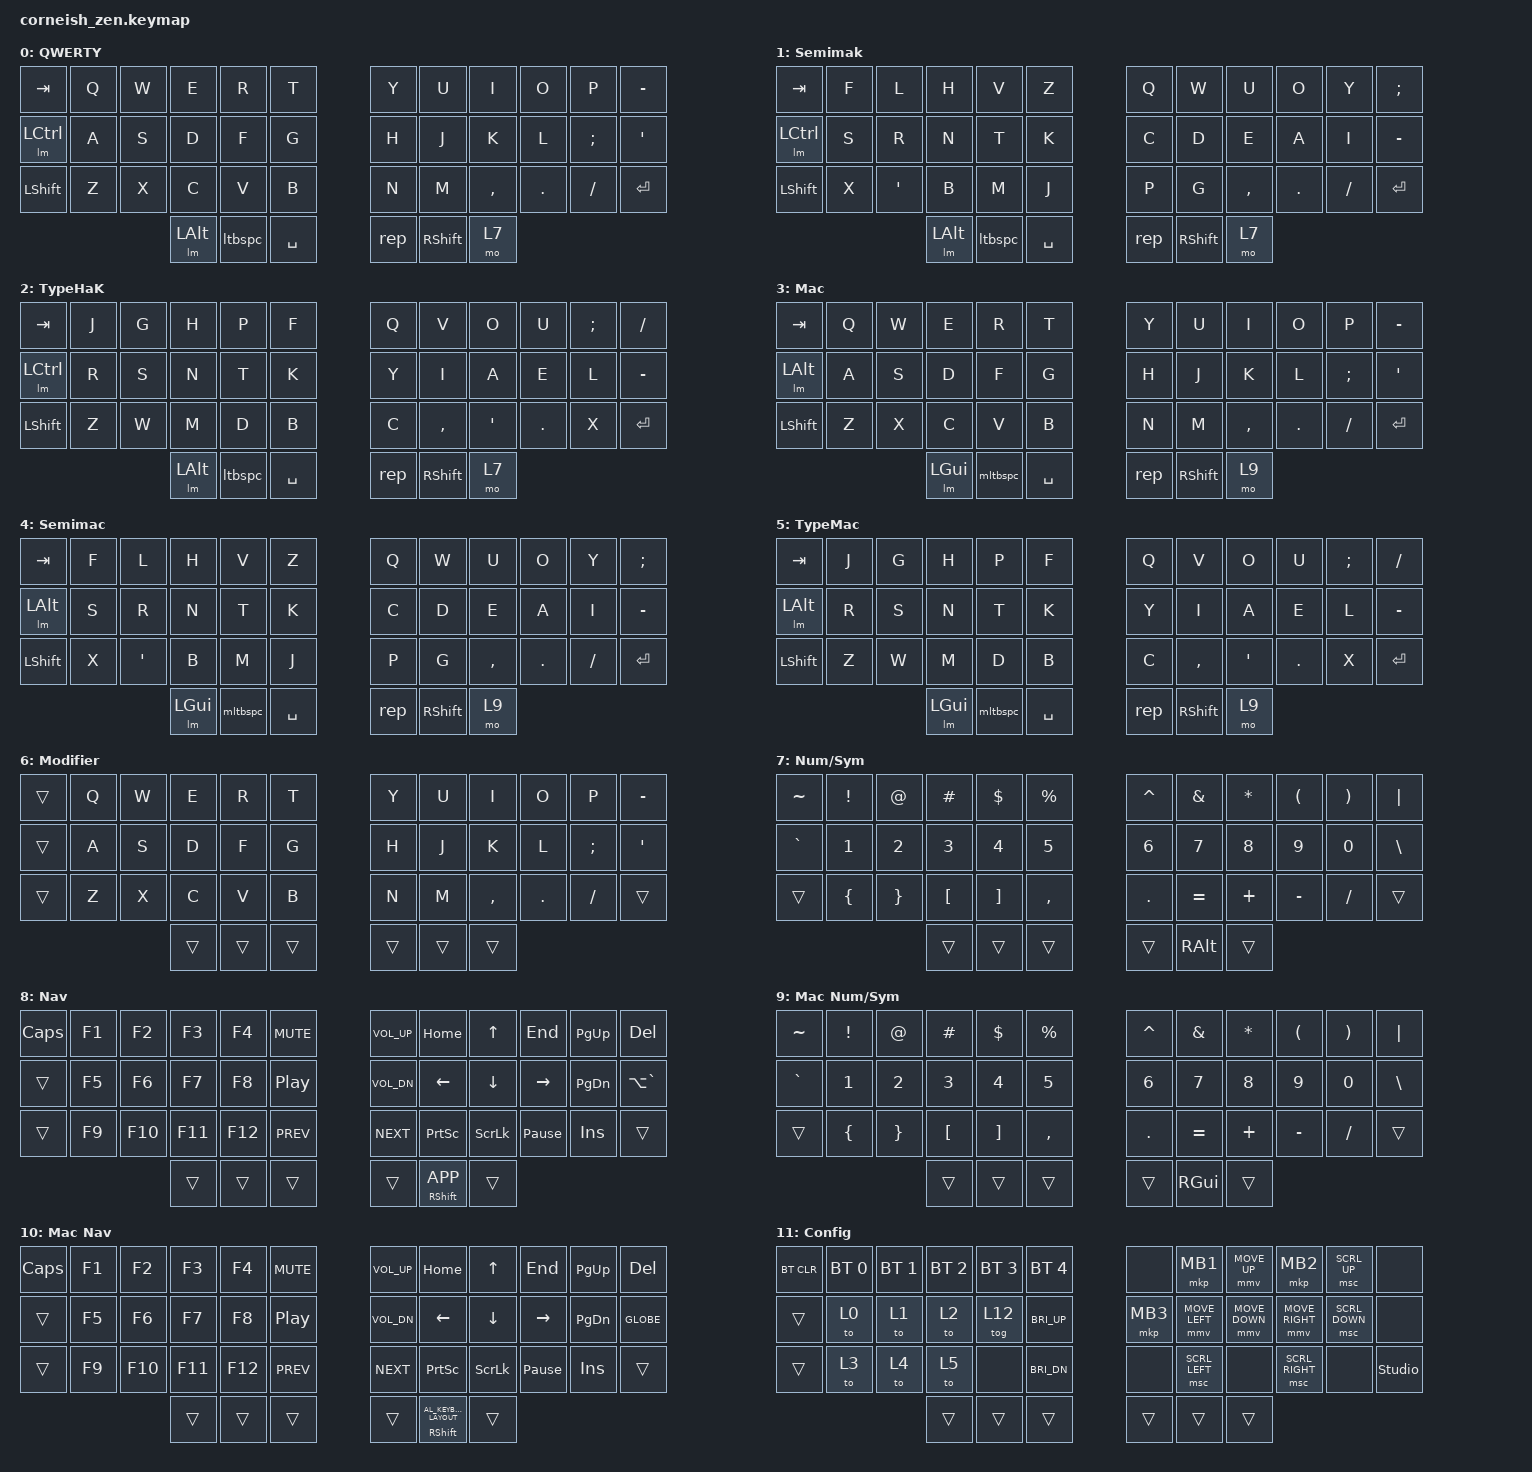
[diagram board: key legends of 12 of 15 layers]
/*
*
* Copyright (c) 2021 Darryl deHaan
* SPDX-License-Identifier: MIT
*
*/

#include <behaviors.dtsi>
#include <dt-bindings/zmk/keys.h>
#include <dt-bindings/zmk/bt.h>
#include <dt-bindings/zmk/outputs.h>

#define ZMK_POINTING_DEFAULT_MOVE_VAL 1800  // default: 600
#define ZMK_POINTING_DEFAULT_SCRL_VAL 20   // default: 10

#include <dt-bindings/zmk/pointing.h>

//Taipo Config
// CONFIG
#define COMBO_TIMEOUT 70
#define COMBO_LAYERS 12
#define STICKY_TIMEOUT 500
#define MOUSE_LEFT 13
#define MOUSE_RIGHT 14

// LEFT SIDE
#define TLI 4 // TOP
#define TLM 3 // TOP
#define TLR 2 // TOP
#define TLP 1 // TOP
#define BLI 16 // BOTTOM
#define BLM 15 // BOTTOM
#define BLR 14 // BOTTOM
#define BLP 13 // BOTTOM
#define LOT 38 // O-THUMB
#define LIT 37 // I-THUMB

// RIGHT SIDE
#define TRI 7 // TOP
#define TRM 8 // TOP
#define TRR 9 // TOP
#define TRP 10 // TOP
#define BRI 19 // BOTTOM
#define BRM 20 // BOTTOM
#define BRR 21 // BOTTOM
#define BRP 22 // BOTTOM
#define ROT 39 // O-THUMB
#define RIT 40 // I-THUMB

&sk {
    release-after-ms = <STICKY_TIMEOUT>;
    quick-release;
};

// 00 01 02 03 04 05	06 07 08 09 10 11
// 12 13 14 15 16 17	18 19 20 21 22 23
// 24 25 26 27 28 29	30 31 32 33 34 35
//          36 37 38	39 40 41


/ {
    chosen {
        zmk,physical-layout = &foostan_corne_6col_layout;
        // zmk,physical-layout = &foostan_corne_5col_layout;
    };
};

/ {
    behaviors {
        kton: key_toggle_on_only {
            compatible = "zmk,behavior-key-toggle";
            #binding-cells = <1>;
            display-name = "Key Toggle On";
            toggle-mode = "on";
        };
        ktoff: key_toggle_off_only {
            compatible = "zmk,behavior-key-toggle";
            #binding-cells = <1>;
            display-name = "Key Toggle Off";
            toggle-mode = "off";
        };
    };
};

/ {
    macros {
        lm: lm {
            compatible = "zmk,behavior-macro-one-param";
            #binding-cells = <1>;
            bindings
                = <&macro_press &mo 6>
                , <&macro_param_1to1>
                , <&macro_press &kp MACRO_PLACEHOLDER>
                , <&macro_pause_for_release>
                , <&macro_param_1to1>
                , <&macro_release &kp MACRO_PLACEHOLDER>
                , <&macro_release &mo 6>
                ;
        };
        skgl: skgl {
            compatible = "zmk,behavior-macro-one-param";
            #binding-cells = <1>;
            bindings
                = <&macro_press &sk GLOBE>
                , <&macro_param_1to1>
                , <&macro_press &sk MACRO_PLACEHOLDER>
                , <&macro_pause_for_release>
                , <&macro_param_1to1>
                , <&macro_release &sk MACRO_PLACEHOLDER>
                , <&macro_release &sk GLOBE>
                ;
        };
        sko: sko {
            compatible = "zmk,behavior-macro-one-param";
            #binding-cells = <1>;
            bindings
                = <&macro_param_1to1>
                , <&macro_press &sk MACRO_PLACEHOLDER>
                , <&macro_pause_for_release>
                , <&macro_param_1to1>
                , <&macro_release &sk MACRO_PLACEHOLDER>
                , <&macro_wait_time STICKY_TIMEOUT>
                , <&macro_param_1to1>
                , <&macro_release &kp MACRO_PLACEHOLDER>
                ;
        };
        modoff: modoff {
            compatible = "zmk,behavior-macro";
            #binding-cells = <0>;
            bindings
                = <&macro_release &kp LGUI &kp LALT &kp LCTRL &kp LSHFT>
                ;
        };
        modoffent: modoffent {
            compatible = "zmk,behavior-macro";
            #binding-cells = <0>;
            bindings
                = <&macro_press &kp ENTER>
                , <&macro_release &kp LGUI &kp LALT &kp LCTRL &kp LSHFT>
                , <&macro_pause_for_release>
                , <&macro_release &kp ENTER>
                ;
        };
    };
};

/ {
    conditional_layers {
        compatible = "zmk,conditional-layers";
        config {
            if-layers = <7 8>;
            then-layer = <11>;
        };
        macconfig {
            if-layers = <9 10>;
            then-layer = <11>;
        };
    };
};

#define rep key_repeat // Repeat Key Alias
#define ltbspc lt 8 BSPC //Backspace when tapped, nav layer when held
#define mltbspc lt 10 BSPC //Backspace when tapped, mac nav layer when held

/ {

    combos {
        compatible = "zmk,combos";
        #include "taipo.dtsi"

        combo_esc {
            timeout-ms = <50>;
            key-positions = <0 1>;
            bindings = <&kp ESC>;
        };
        combo_bspc {
            timeout-ms = <50>;
            key-positions = <11 23>;
            bindings = <&kp BSPC>;
        };
        combo_lgui {
            timeout-ms = <50>;
            key-positions = <36 37>;
            bindings = <&lm LGUI>;
			layers = <0 1 2 7 8>;
        };
        combo_rgui {
            timeout-ms = <50>;
            key-positions = <40 41>;
            bindings = <&lm RGUI>;
            layers = <0 1 2 7 8>;
        };
        combo_lctrl {
            timeout-ms = <50>;
            key-positions = <36 37>;
            bindings = <&lm LCTRL>;
			layers = <3 4 5 9 10>;
        };
        combo_rctrl {
            timeout-ms = <50>;
            key-positions = <40 41>;
            bindings = <&lm RCTRL>;
			layers = <3 4 5 9 10>;
        };
        combo_globe {
            timeout-ms = <50>;
            key-positions = <23 35>;
            bindings = <&lm GLOBE>;
			layers = <3 4 5 9 10>;
        };
        combo_taipo_off {
            timeout-ms = <50>;
            key-positions = <36 41>;
            bindings = <&tog 12>;
			layers = <12>;
        };
        combo_taipo_on_l {
            timeout-ms = <50>;
            key-positions = <00 12 24>;
            bindings = <&tog 12>;
			layers = <0 1 2 3 4 5 6 7 8 9 10 11>;
        };
        combo_taipo_on_r {
            timeout-ms = <50>;
            key-positions = <11 23 35>;
            bindings = <&tog 12>;
			layers = <0 1 2 3 4 5 6 7 8 9 10 11>;
        };
    };

    keymap {
        compatible = "zmk,keymap";

        default_layer {     //0
            display-name = "QWERTY";
// -------------------------------------------------------------------------------
// |  TAB |  Q  |  W  |  E  |  R  |  T  |   |  Y  |  U   |  I  |  O  |  P  |  -  |
// | CTRL |  A  |  S  |  D  |  F  |  G  |   |  H  |  J   |  K  |  L  |  ;  |  '  |
// | SHFT |  Z  |  X  |  C  |  V  |  B  |   |  N  |  M   |  ,  |  .  |  /  | ENT |
//                    | ALT |  BS | SPC |   | REP | SHFT | NUM |
            bindings = <
&kp TAB   &kp Q &kp W &kp E &kp R &kp T   &kp Y &kp U  &kp I     &kp O   &kp P    &kp MINUS
&lm LCTRL &kp A &kp S &kp D &kp F &kp G   &kp H &kp J  &kp K     &kp L   &kp SEMI &kp SQT
&kp LSHFT &kp Z &kp X &kp C &kp V &kp B   &kp N &kp M  &kp COMMA &kp DOT &kp FSLH &kp RET
             &lm LALT &ltbspc &kp SPACE   &rep &kp RSHFT &mo 7
            >;
        };

        semimak_layer {     //1
            display-name = "Semimak";
// -------------------------------------------------------------------------------
// |  TAB |  F  |  L  |  H  |  V  |  Z  |   |  Q  |  W   |  U  |  O  |  Y  |  ;  |
// | CTRL |  S  |  R  |  N  |  T  |  K  |   |  C  |  D   |  E  |  A  |  I  |  -  |
// | SHFT |  X  |  '  |  B  |  M  |  J  |   |  P  |  G   |  ,  |  .  |  /  | ENT |
//                    | ALT |  BS | SPC |   | REP | SHFT | NUM |
            bindings = <
&kp TAB   &kp F &kp L   &kp H &kp V &kp Z   &kp Q &kp W  &kp U     &kp O   &kp Y    &kp SEMI
&lm LCTRL &kp S &kp R   &kp N &kp T &kp K   &kp C &kp D  &kp E     &kp A   &kp I    &kp MINUS
&kp LSHFT &kp X &kp SQT &kp B &kp M &kp J   &kp P &kp G  &kp COMMA &kp DOT &kp FSLH &kp RET
               &lm LALT &ltbspc &kp SPACE   &rep &kp RSHFT &mo 7
            >;
        };

        typehack_layer {    //2
            display-name = "TypeHaK";
// -------------------------------------------------------------------------------
// |  TAB |  J  |  G  |  H  |  P  |  F  |   |  Q  |  V   |  O  |  U  |  ;  |  /  |
// | CTRL |  R  |  S  |  N  |  T  |  K  |   |  Y  |  I   |  A  |  E  |  L  |  -  |
// | SHFT |  Z  |  W  |  M  |  D  |  B  |   |  C  |  ,   |  '  |  .  |  X  | ENT |
//                    | ALT |  BS | SPC |   | REP | SHFT | NUM |
            bindings = <
&kp TAB   &kp J &kp G &kp H &kp P &kp F   &kp Q &kp V     &kp O   &kp U   &kp SEMI &kp FSLH
&lm LCTRL &kp R &kp S &kp N &kp T &kp K   &kp Y &kp I     &kp A   &kp E   &kp L    &kp MINUS
&kp LSHFT &kp Z &kp W &kp M &kp D &kp B   &kp C &kp COMMA &kp SQT &kp DOT &kp X    &kp RET
             &lm LALT &ltbspc &kp SPACE   &rep &kp RSHFT &mo 7
            >;
        };

        mac_layer {     //3
            display-name = "Mac";
// -------------------------------------------------------------------------------
// |  TAB |  Q  |  W  |  E  |  R  |  T  |   |  Y  |  U   |  I  |  O  |  P  |  -  |
// |  ALT |  A  |  S  |  D  |  F  |  G  |   |  H  |  J   |  K  |  L  |  ;  |  '  |
// | SHFT |  Z  |  X  |  C  |  V  |  B  |   |  N  |  M   |  ,  |  .  |  /  | ENT |
//                    | GUI |  BS | SPC |   | REP | SHFT | NUM |
            bindings = <
&kp TAB   &kp Q &kp W &kp E &kp R &kp T   &kp Y &kp U  &kp I     &kp O   &kp P    &kp MINUS
&lm LALT  &kp A &kp S &kp D &kp F &kp G   &kp H &kp J  &kp K     &kp L   &kp SEMI &kp SQT
&kp LSHFT &kp Z &kp X &kp C &kp V &kp B   &kp N &kp M  &kp COMMA &kp DOT &kp FSLH &kp RET
            &lm LGUI &mltbspc &kp SPACE   &rep &kp RSHFT &mo 9
            >;
        };

        semimac_layer {     //4
            display-name = "Semimac";
// -------------------------------------------------------------------------------
// |  TAB |  F  |  L  |  H  |  V  |  Z  |   |  Q  |  W   |  U  |  O  |  Y  |  ;  |
// |  ALT |  S  |  R  |  N  |  T  |  K  |   |  C  |  D   |  E  |  A  |  I  |  -  |
// | SHFT |  X  |  '  |  B  |  M  |  J  |   |  P  |  G   |  ,  |  .  |  /  | ENT |
//                    | GUI |  BS | SPC |   | REP | SHFT | NUM |
            bindings = <
&kp TAB   &kp F &kp L   &kp H &kp V &kp Z   &kp Q &kp W  &kp U     &kp O   &kp Y    &kp SEMI
&lm LALT  &kp S &kp R   &kp N &kp T &kp K   &kp C &kp D  &kp E     &kp A   &kp I    &kp MINUS
&kp LSHFT &kp X &kp SQT &kp B &kp M &kp J   &kp P &kp G  &kp COMMA &kp DOT &kp FSLH &kp RET
              &lm LGUI &mltbspc &kp SPACE   &rep &kp RSHFT &mo 9
            >;
        };

        typemack_layer {    //5
            display-name = "TypeMac";
// -------------------------------------------------------------------------------
// |  TAB |  J  |  G  |  H  |  P  |  F  |   |  Q  |  V   |  O  |  U  |  ;  |  /  |
// |  ALT |  R  |  S  |  N  |  T  |  K  |   |  Y  |  I   |  A  |  E  |  L  |  -  |
// | SHFT |  Z  |  W  |  M  |  D  |  B  |   |  C  |  ,   |  '  |  .  |  X  | ENT |
//                    | GUI |  BS | SPC |   | REP | SHFT | NUM |
            bindings = <
&kp TAB   &kp J &kp G &kp H &kp P &kp F   &kp Q &kp V     &kp O   &kp U   &kp SEMI &kp FSLH
&lm LALT  &kp R &kp S &kp N &kp T &kp K   &kp Y &kp I     &kp A   &kp E   &kp L    &kp MINUS
&kp LSHFT &kp Z &kp W &kp M &kp D &kp B   &kp C &kp COMMA &kp SQT &kp DOT &kp X    &kp RET
            &lm LGUI &mltbspc &kp SPACE   &rep &kp RSHFT &mo 9
            >;
        };

        modifier_layer {    //6
            display-name = "Modifier";
// ------------------------------------------------------------------------------
// |     |  Q  |  W  |  E  |  R  |  T  |   |  Y  |  U   |  I  |  O  |  P  |  /  |
// |     |  A  |  S  |  D  |  F  |  G  |   |  H  |  J   |  K  |  L  |  ;  |  '  |
// |     |  Z  |  X  |  C  |  V  |  B  |   |  N  |  M   |  ,  |  .  |  /  |     |
//                   |     |     |     |   |     |      |     |
            bindings = <
&trans &kp Q &kp W &kp E &kp R &kp T   &kp Y &kp U  &kp I     &kp O   &kp P    &kp MINUS
&trans &kp A &kp S &kp D &kp F &kp G   &kp H &kp J  &kp K     &kp L   &kp SEMI &kp SQT
&trans &kp Z &kp X &kp C &kp V &kp B   &kp N &kp M  &kp COMMA &kp DOT &kp FSLH &trans  
                &trans &trans &trans   &trans &trans &trans  
            >;
        };

        number_layer {      //7
            display-name = "Num/Sym";
// -----------------------------------------------------------------------------
// |  ~  |  !  |  @  |  #  |  $  |  %  |   |  ^  |  &  |  *  |  (  |  )  |  |  |
// |  `  |  1  |  2  |  3  |  4  |  5  |   |  6  |  7  |  8  |  9  |  0  |  \  |
// |     |  {  |  }  |  [  |  ]  |  ,  |   |  .  |  =  |  +  |  -  |  /  |     |
//                   |     |     |     |   |     | ALT |     |
            bindings = <
&kp TILDE &kp EXCL  &kp AT   &kp HASH &kp DLLR &kp PRCNT   &kp CARET &kp AMPS   &kp STAR &kp LPAR  &kp RPAR &kp PIPE
&kp GRAVE &kp N1    &kp N2   &kp N3   &kp N4   &kp N5      &kp N6    &kp N7     &kp N8   &kp N9    &kp N0   &kp BSLH
&trans    &kp LBRC  &kp RBRC &kp LBKT &kp RBKT &kp COMMA   &kp DOT   &kp EQUAL  &kp PLUS &kp MINUS &kp FSLH &trans
                          	        &trans &trans &trans   &trans &kp RALT &trans
            >;
        };

        navigation_layer {  //8
            display-name = "Nav";
// -----------------------------------------------------------------------------
// | CAP |  F1 |  F2 |  F3 |  F4 | MUT |   | VUP | HME |  UP | END | PGU | DEL |
// |     |  F5 |  F6 |  F7 |  F8 | PP  |   | VDN | LFT | DWN | RGT | PGD |     |
// |     |  F9 | F10 | F11 | F12 | PRV |   | NXT | PRN | SCL | PSE | INS |     |
//                   |     |     |     |   |     |     |     |
            bindings = <
&kp CAPS &kp F1 &kp F2  &kp F3  &kp F4  &kp C_MUTE   &kp C_VOL_UP &kp HOME  &kp UP   &kp END         &kp PG_UP &kp DEL
&trans   &kp F5 &kp F6  &kp F7  &kp F8  &kp C_PP     &kp C_VOL_DN &kp LEFT  &kp DOWN &kp RIGHT       &kp PG_DN &kp LA(GRAVE)
&trans   &kp F9 &kp F10 &kp F11 &kp F12 &kp C_PREV   &kp C_NEXT   &kp PSCRN &kp SLCK &kp PAUSE_BREAK &kp INS   &trans
                              &trans &trans &trans   &trans &mt RSHFT K_APP &trans
            >;
        };

        macnum_layer {      //9
            display-name = "Mac Num/Sym";
// -----------------------------------------------------------------------------
// |  ~  |  !  |  @  |  #  |  $  |  %  |   |  ^  |  &  |  *  |  (  |  )  |  |  |
// |  `  |  1  |  2  |  3  |  4  |  5  |   |  6  |  7  |  8  |  9  |  0  |  \  |
// |     |  {  |  }  |  [  |  ]  |  ,  |   |  .  |  =  |  +  |  -  |  /  |     |
//                   |     |     |     |   |     | GUI |     |
            bindings = <
&kp TILDE &kp EXCL  &kp AT   &kp HASH &kp DLLR &kp PRCNT   &kp CARET &kp AMPS   &kp STAR &kp LPAR  &kp RPAR &kp PIPE
&kp GRAVE &kp N1    &kp N2   &kp N3   &kp N4   &kp N5      &kp N6    &kp N7     &kp N8   &kp N9    &kp N0   &kp BSLH
&trans    &kp LBRC  &kp RBRC &kp LBKT &kp RBKT &kp COMMA   &kp DOT   &kp EQUAL  &kp PLUS &kp MINUS &kp FSLH &trans
                          	        &trans &trans &trans   &trans &kp RGUI &trans
            >;
        };

        macnav_layer {      //10
            display-name = "Mac Nav";
// -----------------------------------------------------------------------------
// | CAP |  F1 |  F2 |  F3 |  F4 | MUT |   | VUP | HME |  UP | END | PGU | DEL |
// |     |  F5 |  F6 |  F7 |  F8 | PP  |   | VDN | LFT | DWN | RGT | PGD |     |
// |     |  F9 | F10 | F11 | F12 | PRV |   | NXT | PRN | SCL | PSE | INS |     |
//                   |     |     |     |   |     |     |     |
            bindings = <
&kp CAPS &kp F1 &kp F2  &kp F3  &kp F4  &kp C_MUTE   &kp C_VOL_UP &kp HOME  &kp UP   &kp END         &kp PG_UP &kp DEL
&trans   &kp F5 &kp F6  &kp F7  &kp F8  &kp C_PP     &kp C_VOL_DN &kp LEFT  &kp DOWN &kp RIGHT       &kp PG_DN &kp GLOBE
&trans   &kp F9 &kp F10 &kp F11 &kp F12 &kp C_PREV   &kp C_NEXT   &kp PSCRN &kp SLCK &kp PAUSE_BREAK &kp INS   &trans
                              &trans &trans &trans   &trans &mt RSHFT C_AL_KEYBOARD_LAYOUT &trans
            >;
        };

        config_layer {      //11
            display-name = "Config";
// --------------------------------------------------------------------------------------
// | BTCLR | BT1 | BT2 | BT3 | BT4 | BT5 |   |     | MB1  | MSUP | MB2  | SCUP |        |
// |       | QWE | SEM | TYP | TAI |     |   | MB3 | MSLF | MSDN | MSRT | SCDN |        |
// |       | MAC | SMC | TYM |     |     |   |     | SCLF |      | SCRT |      | UNLOCK |
//                     |     |     |     |   |     |      |      |
            bindings = <
&bt BT_CLR &bt BT_SEL 0 &bt BT_SEL 1 &bt BT_SEL 2 &bt BT_SEL 3 &bt BT_SEL 4   &none    &mkp MB1       &mmv MOVE_UP   &mkp MB2        &msc SCRL_UP   &none
&trans     &to 0        &to 1        &to 2        &tog 12      &kp C_BRI_UP   &mkp MB3 &mmv MOVE_LEFT &mmv MOVE_DOWN &mmv MOVE_RIGHT &msc SCRL_DOWN &none
&trans     &to 3        &to 4        &to 5        &none        &kp C_BRI_DN   &none    &msc SCRL_LEFT &none          &msc SCRL_RIGHT &none          &studio_unlock
                                                       &trans &trans &trans   &trans &trans &trans
            >;
        };

        taipo_layer {      //12
            display-name = "Taipo";
            bindings = <
&none &none &none &none &none &none     &none &none &none &none &none &none
&none &none &none &none &none &none     &none &none &none &none &none &none
&none &none &none &none &none &none     &none &none &none &none &none &none
                  &none &none &none     &none &none &none
            >;
        };
        taipomouseleft_layer {      //13
            display-name = "TMLeft";
            bindings = <
&none &msc SCRL_UP   &mkp MB2       &mmv MOVE_UP   &mkp MB1        &none     &none &none &none &none &none &none
&none &msc SCRL_DOWN &mmv MOVE_LEFT &mmv MOVE_DOWN &mmv MOVE_RIGHT &none     &none &none &none &none &none &none
&none &none          &none          &none          &none           &none     &none &none &none &none &none &none
                                                       &none &none &none     &none &none &none
            >;
        };
        taipomouseright_layer {      //14
            display-name = "TMRight";
            bindings = <
&none &none &none &none &none &none     &none &mkp MB1       &mmv MOVE_UP   &mkp MB2        &msc SCRL_UP   &none
&none &none &none &none &none &none     &none &mmv MOVE_LEFT &mmv MOVE_DOWN &mmv MOVE_RIGHT &msc SCRL_DOWN &none
&none &none &none &none &none &none     &none &none          &none          &none           &none          &none
                  &none &none &none     &none &none &none
            >;
        };
    };
};
